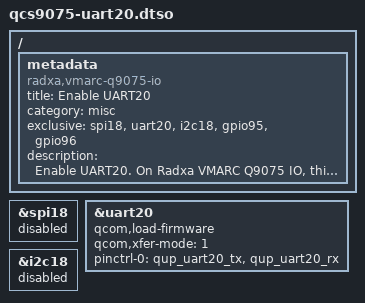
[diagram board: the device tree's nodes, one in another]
// SPDX-License-Identifier: BSD-3-Clause
/*
 * Copyright (c) 2026 Radxa Computer (Shenzhen) Co., Ltd.
 */

/dts-v1/;
/plugin/;

/ {
    metadata {
        title = "Enable UART20";
        compatible = "radxa,vmarc-q9075-io";
        category = "misc";
        exclusive = "spi18", "uart20", "i2c18", "gpio95", "gpio96";
        description = "Enable UART20.
On Radxa VMARC Q9075 IO, this is pin 27(tx) & pin 28(rx).";
    };
};

&spi18 {
	status = "disabled";
};

&uart20 {
	qcom,load-firmware;
	qcom,xfer-mode = <1>; 
	status = "okay";
	pinctrl-0 = <&qup_uart20_tx>, <&qup_uart20_rx>;
	pinctrl-names = "default";
};

&i2c18 {
	status = "disabled";
};
